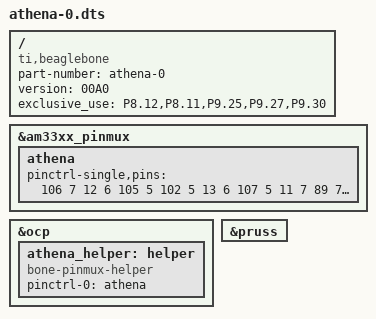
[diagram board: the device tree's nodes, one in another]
/* athena-0.dts - device tree source for Franklin on Athena
 * Copyright 2014-2016 Michigan Technological University
 * Copyright 2016 Bas Wijnen <wijnen@debian.org>
 * Author: Bas Wijnen <wijnen@debian.org>
 *
 * This program is free software: you can redistribute it and/or modify
 * it under the terms of the GNU Affero General Public License as
 * published by the Free Software Foundation, either version 3 of the
 * License, or (at your option) any later version.
 *
 * This program is distributed in the hope that it will be useful,
 * but WITHOUT ANY WARRANTY; without even the implied warranty of
 * MERCHANTABILITY or FITNESS FOR A PARTICULAR PURPOSE.  See the
 * GNU Affero General Public License for more details.
 *
 * You should have received a copy of the GNU Affero General Public License
 * along with this program.  If not, see <http://www.gnu.org/licenses/>.
 */
/dts-v1/;
/plugin/;
/ { compatible = "ti,beaglebone", "ti,beaglebone-black";
	/* identification */
	part-number = "athena-0";
	version = "00A0";
	exclusive_use = "P8.12,P8.11,P9.25,P9.27,P9.30";
	fragment@0 {
		target = <&am33xx_pinmux>;
		__overlay__ {
			athena {
				pinctrl-single,pins = <
				106 7 /*59 7	/* disable HDMI audio clock */
				12 6 /*44	dir */
				105 5 /*115	step 0 */
				102 5 /*112	step 1 */
				13 6 /*45	step 2 */
				107 5 /*117	step 3 */
				11 7 /*27	enable 0 */
				89 7 /*7	enable 1 */
				97 7 /*15	enable 2 */
				96 7 /*14	enable 3 */
				18 0x17 /*50	limit 0 */
				30 0x17 /*60	limit 1 */
				28 0x17 /*30	limit 2 */
				36 7 /*66	mosfet 0 */
				39 7 /*69	mosfet 1 */
				>;
			};
		};
	};

	fragment@1 {
		target = <&ocp>;
		__overlay__ {
			athena_helper: helper {
				compatible = "bone-pinmux-helper";
				pinctrl-names = "default";
				pinctrl-0 = <&athena>;
				status = "okay";
			};
		};
	};

	fragment@2 {
		target = <&pruss>;
		__overlay__ {
			status = "okay";
		};
	};
};
